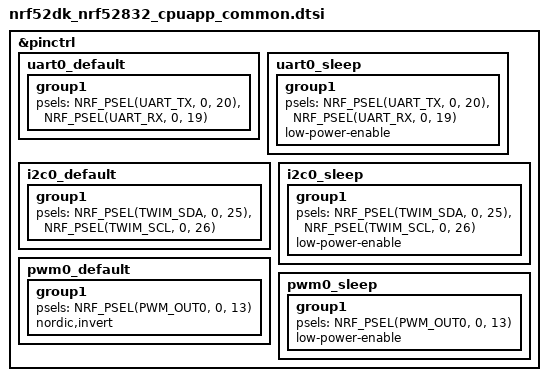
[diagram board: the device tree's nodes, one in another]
/*
 * Copyright (c) 2024 Nordic Semiconductor ASA
 *
 * SPDX-License-Identifier: LicenseRef-Nordic-5-Clause
 */

&pinctrl {
	uart0_default: uart0_default {
		group1 {
			psels = <NRF_PSEL(UART_TX, 0, 20)>,
					<NRF_PSEL(UART_RX, 0, 19)>;
		};
	};

	uart0_sleep: uart0_sleep {
		group1 {
			psels = <NRF_PSEL(UART_TX, 0, 20)>,
					<NRF_PSEL(UART_RX, 0, 19)>;
			low-power-enable;
		};
	};

	i2c0_default: i2c0_default {
		group1 {
			psels = <NRF_PSEL(TWIM_SDA, 0, 25)>,
					<NRF_PSEL(TWIM_SCL, 0, 26)>;
		};
	};

	i2c0_sleep: i2c0_sleep {
		group1 {
			psels = <NRF_PSEL(TWIM_SDA, 0, 25)>,
					<NRF_PSEL(TWIM_SCL, 0, 26)>;
			low-power-enable;
		};
	};

	/*i2c1_default: i2c1_default {
		group1 {
			psels = <NRF_PSEL(TWIM_SDA, 0, 25)>,
					<NRF_PSEL(TWIM_SCL, 0, 26)>;
		};
	};

	i2c1_sleep: i2c1_sleep {
		group1 {
			psels = <NRF_PSEL(TWIM_SDA, 0, 25)>,
					<NRF_PSEL(TWIM_SCL, 0, 26)>;
			low-power-enable;
		};
	};*/

	pwm0_default: pwm0_default {
		group1 {
			psels = <NRF_PSEL(PWM_OUT0, 0, 13)>;
			nordic,invert;
		};
	};

	pwm0_sleep: pwm0_sleep {
		group1 {
			psels = <NRF_PSEL(PWM_OUT0, 0, 13)>;
			low-power-enable;
		};
	};

	/*spi0_default: spi0_default {
		group1 {
			psels = <NRF_PSEL(SPIM_SCK, 0, 26)>,
					<NRF_PSEL(SPIM_MOSI, 0, 25)>,
					<NRF_PSEL(SPIM_MISO, 0, 28)>;
		};
	};

	spi0_sleep: spi0_sleep {
		group1 {
			psels = <NRF_PSEL(SPIM_SCK, 0, 26)>,
					<NRF_PSEL(SPIM_MOSI, 0, 25)>,
					<NRF_PSEL(SPIM_MISO, 0, 28)>;
			low-power-enable;
		};
	};*/

	/*spi1_default: spi1_default {
		group1 {
			psels = <NRF_PSEL(SPIM_SCK, 0, 8)>,
					<NRF_PSEL(SPIM_MOSI, 0, 7)>,
					<NRF_PSEL(SPIM_MISO, 0, 6)>;
		};
	};

	spi1_sleep: spi1_sleep {
		group1 {
			psels = <NRF_PSEL(SPIM_SCK, 0, 8)>,
					<NRF_PSEL(SPIM_MOSI, 0, 7)>,
					<NRF_PSEL(SPIM_MISO, 0, 6)>;
			low-power-enable;
		};
	};*/

	/*spi2_default: spi2_default {
		group1 {
			psels = <NRF_PSEL(SPIM_SCK, 0, 22)>,
					<NRF_PSEL(SPIM_MOSI, 0, 23)>,
					<NRF_PSEL(SPIM_MISO, 0, 24)>;
		};
	};

	spi2_sleep: spi2_sleep {
		group1 {
			psels = <NRF_PSEL(SPIM_SCK, 0, 22)>,
					<NRF_PSEL(SPIM_MOSI, 0, 23)>,
					<NRF_PSEL(SPIM_MISO, 0, 24)>;
			low-power-enable;
		};
	};*/
};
